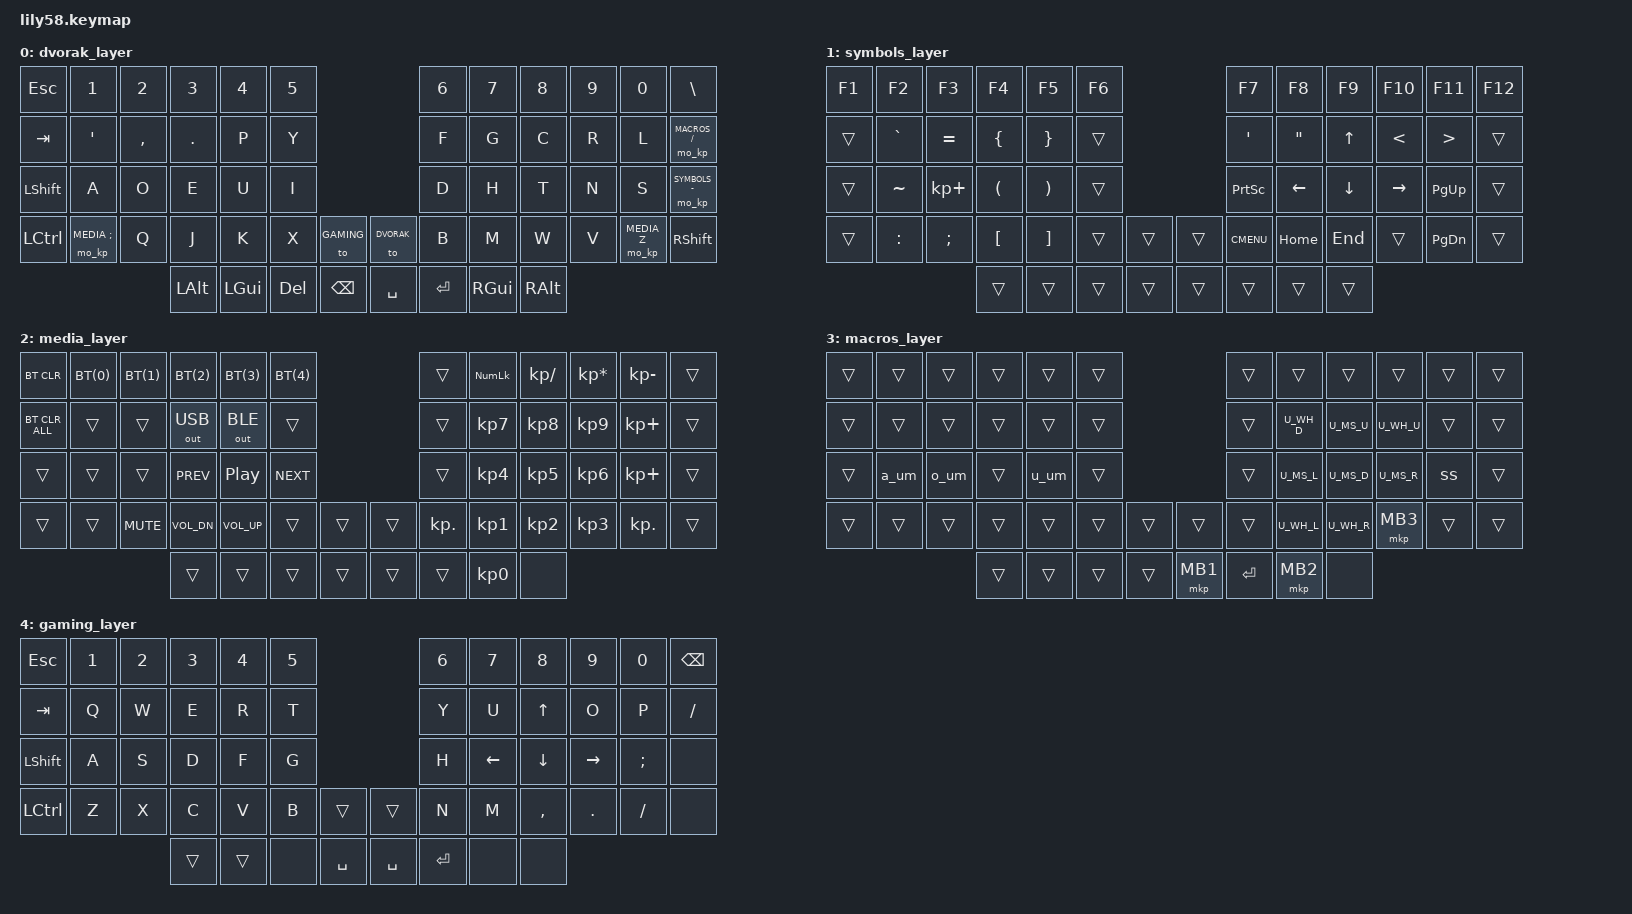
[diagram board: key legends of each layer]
#include <behaviors.dtsi>
#include <dt-bindings/zmk/keys.h>
#include <dt-bindings/zmk/bt.h>
#include <dt-bindings/zmk/ext_power.h>
#include <dt-bindings/zmk/outputs.h>

#include "zmk-helpers/helper.h"

#define DVORAK       0
#define SYMBOLS      1
#define MEDIA        2
#define MACROS       3
#define GAMING       4

#include "macros.dtsi"
#include "combos.dtsi"
#include "custom_behaviors.dtsi"
#include "mouse.dtsi"

#define SEMI_MED &mo_kp MEDIA SEMI
#define Z_MED &mo_kp MEDIA Z
#define DASH_SYM &mo_kp SYMBOLS MINUS
#define SLASH_MAC &mo_kp MACROS SLASH
#define BT(profile) &bt BT_SEL profile

/ {
	keymap {
		compatible = "zmk,keymap";

        dvorak_layer {
			bindings = <
// ┌─────────┬─────────┬─────────┬─────────┬─────────┬─────────┐                     ┌─────────┬─────────┬─────────┬─────────┬─────────┬─────────┐
    &kp ESC   &kp N1    &kp N2    &kp N3    &kp N4    &kp N5                          &kp N6    &kp N7    &kp N8    &kp N9    &kp N0    &kp BSLH
// ├─────────┼─────────┼─────────┼─────────┼─────────┼─────────┤                     ├─────────┼─────────┼─────────┼─────────┼─────────┼─────────┤
    &kp TAB   &kp SQT  &kp COMMA &kp PERIOD &kp P     &kp Y                           &kp F     &kp G     &kp C     &kp R     &kp L     SLASH_MAC
// ├─────────┼─────────┼─────────┼─────────┼─────────┼─────────┤                     ├─────────┼─────────┼─────────┼─────────┼─────────┼─────────┤
    &kp LSHFT &kp A     &kp O     &kp E     &kp U     &kp I                           &kp D     &kp H     &kp T     &kp N     &kp S     DASH_SYM
// ├─────────┼─────────┼─────────┼─────────┼─────────┼─────────┼─────────┐ ┌─────────┼─────────┼─────────┼─────────┼─────────┼─────────┼─────────┤
    &kp LCTRL SEMI_MED  &kp Q     &kp J     &kp K     &kp X    &to GAMING  &to DVORAK &kp B     &kp M     &kp W     &kp V     Z_MED     &kp RSHFT
// └─────────┴─────────┴─────────┼─────────┼─────────┼─────────┼─────────┤ ├─────────┼─────────┼─────────┼─────────┼─────────┴─────────┴─────────┘
                                  &kp LALT  &kp LGUI  &kp DEL   &kp BSPC    &kp SPACE &kp RET   &kp RGUI  &kp RALT
                              // └─────────┴─────────┴─────────┴─────────┘ └─────────┴─────────┴─────────┴─────────┘
			>; 
		};

		symbols_layer {
			bindings = <
// ┌─────────┬─────────┬─────────┬─────────┬─────────┬─────────┐                     ┌─────────┬─────────┬─────────┬─────────┬─────────┬─────────┐
    &kp F1    &kp F2    &kp F3    &kp F4    &kp F5    &kp F6                          &kp F7    &kp F8    &kp F9    &kp F10   &kp F11   &kp F12
// ├─────────┼─────────┼─────────┼─────────┼─────────┼─────────┤                     ├─────────┼─────────┼─────────┼─────────┼─────────┼─────────┤
    &trans    &kp GRAVE &kp EQUAL &kp LBRC  &kp RBRC  &trans                          &kp SQT   &kp DQT   &kp UP    &kp LT    &kp GT    &trans
// ├─────────┼─────────┼─────────┼─────────┼─────────┼─────────┤                     ├─────────┼─────────┼─────────┼─────────┼─────────┼─────────┤
    &trans    &kp TILDE &kp KP_PLUS &kp LPAR &kp RPAR &trans                          &kp PSCRN &kp LEFT  &kp DOWN  &kp RIGHT &kp PG_UP &trans
// ├─────────┼─────────┼─────────┼─────────┼─────────┼─────────┼─────────┐ ┌─────────┼─────────┼─────────┼─────────┼─────────┼─────────┼─────────┤
    &trans    &kp COLON &kp SEMI  &kp LBKT  &kp RBKT  &trans    &trans      &trans  &kp K_CMENU &kp HOME  &kp END   &trans	  &kp PG_DN &trans
// └─────────┴─────────┴─────────┼─────────┼─────────┼─────────┼─────────┤ ├─────────┼─────────┼─────────┼─────────┼─────────┴─────────┴─────────┘
                                  &trans    &trans    &trans    &trans      &trans    &trans    &trans    &trans
                              // └─────────┴─────────┴─────────┴─────────┘ └─────────┴─────────┴─────────┴─────────┘
			>;
		};

		media_layer {
			bindings = <
// ┌─────────┬─────────┬─────────┬─────────┬─────────┬─────────┐                     ┌─────────┬─────────┬─────────┬─────────┬─────────┬─────────┐
   &bt BT_CLR BT(0)     BT(1)     BT(2)     BT(3)     BT(4)                        &trans &kp KP_NUM &kp KP_SLASH &kp KP_MULTIPLY &kp KP_MINUS &trans
// ├─────────┼─────────┼─────────┼─────────┼─────────┼─────────┤                     ├─────────┼─────────┼─────────┼─────────┼─────────┼─────────┤
  &bt BT_CLR_ALL &trans &trans  &out OUT_USB &out OUT_BLE &trans                      &trans    &kp KP_N7 &kp KP_N8 &kp KP_N9 &kp KP_PLUS &trans
// ├─────────┼─────────┼─────────┼─────────┼─────────┼─────────┤                     ├─────────┼─────────┼─────────┼─────────┼─────────┼─────────┤
    &trans    &trans    &trans   &kp C_PREV &kp C_PP  &kp C_NEXT                      &trans    &kp KP_N4 &kp KP_N5 &kp KP_N6 &kp KP_PLUS &trans
// ├─────────┼─────────┼─────────┼─────────┼─────────┼─────────┼─────────┐ ┌─────────┼─────────┼─────────┼─────────┼─────────┼─────────┼─────────┤
    &trans    &trans &kp C_MUTE &kp C_VOL_DN &kp C_VOL_UP &trans &trans     &trans   &kp KP_DOT &kp KP_N1 &kp KP_N2 &kp KP_N3 &kp KP_DOT  &trans
// └─────────┴─────────┴─────────┼─────────┼─────────┼─────────┼─────────┤ ├─────────┼─────────┼─────────┼─────────┼─────────┴─────────┴─────────┘
                                  &trans    &trans    &trans    &trans      &trans    &trans    &kp KP_N0 &none
                              // └─────────┴─────────┴─────────┴─────────┘ └─────────┴─────────┴─────────┴─────────┘
			>;
		};

        macros_layer {
			bindings = <
// ┌─────────┬─────────┬─────────┬─────────┬─────────┬─────────┐                     ┌─────────┬─────────┬─────────┬─────────┬─────────┬─────────┐
    &trans    &trans    &trans    &trans    &trans    &trans                          &trans    &trans    &trans    &trans    &trans    &trans
// ├─────────┼─────────┼─────────┼─────────┼─────────┼─────────┤                     ├─────────┼─────────┼─────────┼─────────┼─────────┼─────────┤
    &trans    &trans    &trans    &trans    &trans    &trans                          &trans    U_WH_D    U_MS_U    U_WH_U    &trans    &trans
// ├─────────┼─────────┼─────────┼─────────┼─────────┼─────────┤                     ├─────────┼─────────┼─────────┼─────────┼─────────┼─────────┤
    &trans    &a_um     &o_um     &trans    &u_um     &trans                          &trans    U_MS_L    U_MS_D    U_MS_R    &ss       &trans
// ├─────────┼─────────┼─────────┼─────────┼─────────┼─────────┼─────────┐ ┌─────────┼─────────┼─────────┼─────────┼─────────┼─────────┼─────────┤
    &trans    &trans    &trans    &trans    &trans    &trans    &trans      &trans    &trans    U_WH_L    U_WH_R    &mkp MB3  &trans    &trans
// └─────────┴─────────┴─────────┼─────────┼─────────┼─────────┼─────────┤ ├─────────┼─────────┼─────────┼─────────┼─────────┴─────────┴─────────┘
                                  &trans    &trans    &trans    &trans      &mkp MB1  &kp RET   &mkp MB2  &none
                              // └─────────┴─────────┴─────────┴─────────┘ └─────────┴─────────┴─────────┴─────────┘
			>;
		};

        gaming_layer {
			bindings = <
// ┌─────────┬─────────┬─────────┬─────────┬─────────┬─────────┐                     ┌─────────┬─────────┬─────────┬─────────┬─────────┬─────────┐
    &kp ESC   &kp N1    &kp N2    &kp N3    &kp N4    &kp N5                          &kp N6    &kp N7    &kp N8    &kp N9    &kp N0    &kp BSPC
// ├─────────┼─────────┼─────────┼─────────┼─────────┼─────────┤                     ├─────────┼─────────┼─────────┼─────────┼─────────┼─────────┤
    &kp TAB   &kp Q     &kp W     &kp E     &kp R     &kp T                           &kp Y     &kp U     &kp UP    &kp O     &kp P     &kp SLASH
// ├─────────┼─────────┼─────────┼─────────┼─────────┼─────────┤                     ├─────────┼─────────┼─────────┼─────────┼─────────┼─────────┤
    &kp LSHFT &kp A     &kp S     &kp D     &kp F     &kp G                           &kp H     &kp LEFT  &kp DOWN  &kp RIGHT &kp SEMI  &none
// ├─────────┼─────────┼─────────┼─────────┼─────────┼─────────┼─────────┐ ┌─────────┼─────────┼─────────┼─────────┼─────────┼─────────┼─────────┤
    &kp LCTRL &kp Z     &kp X     &kp C     &kp V     &kp B     &trans      &trans    &kp N     &kp M     &kp COMMA &kp DOT   &kp FSLH  &none
// └─────────┴─────────┴─────────┼─────────┼─────────┼─────────┼─────────┤ ├─────────┼─────────┼─────────┼─────────┼─────────┴─────────┴─────────┘
                                  &trans    &trans    &none     &kp SPACE   &kp SPACE &kp RET   &none     &none
                              // └─────────┴─────────┴─────────┴─────────┘ └─────────┴─────────┴─────────┴─────────┘
			>; 
		};
	};
};
